# RA4M1 register map
Vendor: Renesas Electronics Corporation; Series: RA4; File version: 1.2
CPU: CM4 r0p1, little endian, MPU, FPU, VTOR, 4 interrupt priority bits
Registers are 8-bit, read-write, reset 0x0 unless marked. A register's access mark holds for its fields unless they carry their own. Offsets are from the block's base; [hi:lo] are bit positions; 'fields as' and 'values as' point back to an identical list; <NAME> marks a mode.

## ACMPLP — Low-Power Analog Comparator
Base 0x40085E00
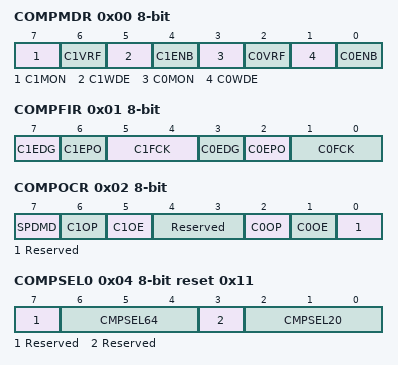
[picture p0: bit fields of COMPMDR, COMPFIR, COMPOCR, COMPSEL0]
0x00 COMPMDR — ACMPLP Mode Setting Register
  [7] C1MON ro — ACMPLP1 Monitor Flag
    0=CMPIN1 < CMPREF1, CMPIN1 < internal reference voltage, or ACMPLP1 operation disabled.(When the window function is disabled)/CMPIN1 < VRFL, CMPIN1 > VRFH, or ACMPLP1 operation disabled.(When the window function is enabled); 1=CMPIN1 > CMPREF1, or CMPIN1 > internal reference voltage.(When the window function is disabled)/VRFL < CMPIN1 < VRFH.(When the window function is enabled)
  [6] C1VRF — ACMPLP1 Reference Voltage Selection
    0=IVREF0 or IVREF1; 1=internal reference voltage (Vref)
  [5] C1WDE — ACMPLP1 Window Function Mode Enable
    0=Disabled; 1=Enabled
  [4] C1ENB — ACMPLP1 Operation Enable
    0=Disabled; 1=Enabled
  [3] C0MON ro — ACMPLP0 Monitor Flag
    0=CMPIN0 < CMPREF0, CMPIN0 < internal reference voltage, or ACMPLP0 operation disabled.(When the window function is disabled)/CMPIN0 < VRFL, CMPIN0 > VRFH, or ACMPLP0 operation disabled.(When the window function is enabled); 1=CMPIN0 > CMPREF0, or CMPIN0 > internal reference voltage.(When the window function is disabled)/VRFL < CMPIN0 < VRFH.(When the window function is enabled)
  [2] C0VRF — ACMPLP0 Reference Voltage Selection
    0=IVREF0; 1=internal reference voltage (Vref)
  [1] C0WDE — ACMPLP0 Window Function Mode Enable
    0=Disabled; 1=Enabled
  [0] C0ENB — ACMPLP0 Operation Enable
    0=Disabled; 1=Enabled
0x01 COMPFIR — ACMPLP Filter Control Register
  [7] C1EDG — ACMPLP1 Edge Detection Selection
    0=Interrupt and ELC event request by one-edge detection; 1=Interrupt and ELC event request by both-edge detection
  [6] C1EPO — ACMPLP1 Edge Polarity Switching
    0=Interrupt and ELC event request at rising edge; 1=Interrupt and ELC event request at falling edge
  [5:4] C1FCK — ACMPLP1 Filter Select
    0=No Sampling (bypass); 1=Sampling at PCLK; 2=Sampling at PCLK/8; 3=Sampling at PCLK/32
  [3] C0EDG — ACMPLP0 Edge Detection Selection
    values as C1EDG
  [2] C0EPO — ACMPLP0 Edge Polarity Switching
    values as C1EPO
  [1:0] C0FCK — ACMPLP0 Filter Select
    values as C1FCK
0x02 COMPOCR — ACMPLP Output Control Register
  [7] SPDMD — ACMPLP0/ACMPLP1 Speed Selection
    0=Comparator low-speed mode; 1=Comparator high-speed mode
  [6] C1OP — ACMPLP1 VCOUT Output Polarity Selection
    0=Non inverted; 1=Inverted
  [5] C1OE — ACMPLP1 VCOUT Pin Output Enable
    0=Disabled; 1=Enabled
  [4:3] Reserved — These bits are read as 00. The write value should be 00.
  [2] C0OP — ACMPLP0 VCOUT Output Polarity Selection
    0=Non inverted; 1=Inverted
  [1] C0OE — ACMPLP0 VCOUT Pin Output Enable
    0=Disabled; 1=Enabled
  [0] Reserved — This bit is read as 0. The write value should be 0.
0x04 COMPSEL0 reset 0x11 — Comparator Input Select Register
  [7] Reserved — This bit is read as 0. The write value should be 0.
  [6:4] CMPSEL64 — ACMPLP1 Input (IVCMP1) Selection
    0=No input; 1=CMPIN1 (P102); 4=CMPIN1 (P501); other=others (settings prohibited)
  [3] Reserved — This bit is read as 0. The write value should be 0.
  [2:0] CMPSEL20 — ACMPLP0 Input(IVCMP0) Selection
    0=No input; 1=CMPIN0 (P100); 4=CMPIN0 (P503); other=others (settings prohibited)
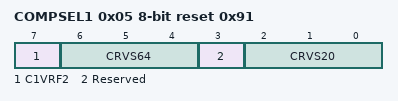
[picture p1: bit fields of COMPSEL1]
0x05 COMPSEL1 reset 0x91 — Comparator Reference Voltage Select Register
  [7] C1VRF2 — ACMPLP1 Reference Voltage Selection
    0=IVREF0 selected; 1=IVREF1 selected
  [6:4] CRVS64 — ACMPLP1 Reference Voltage(IVREF1) Selection
    0=No input; 1=CMPREF1 (P103); 2=DAC8 (ch1) output; 4=CMPREF1 (P500); other=others (settings prohibited.)
  [3] Reserved — This bit is read as 0. The write value should be 0.
  [2:0] CRVS20 — ACMPLP0 Reference Voltage(IVREF0) Selection*
    0=No input; 1=CMPREF0 (P101); 2=DAC8 (ch0) output; 4=CMPREF0 (P502); other=others (settings prohibited.)
